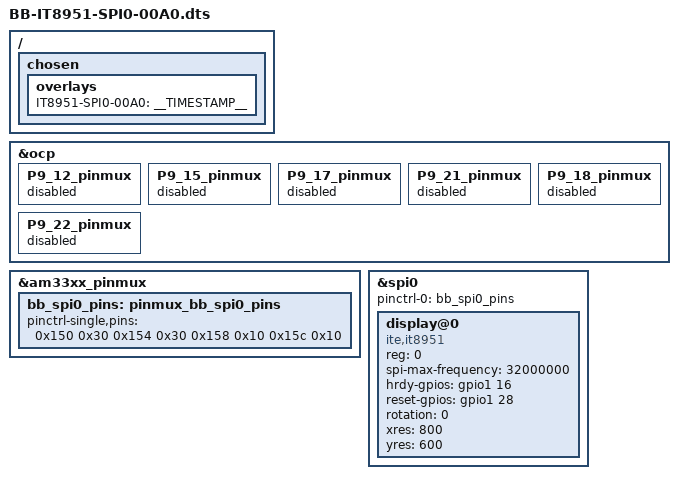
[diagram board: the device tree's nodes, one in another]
/*
 * Copyright (C) 2013 CircuitCo
 * Copyright (C) 2018 Drew Fustini <drew@beagleboard.org>
 * Copyright (C) 2019 Mark A. Yoder <mark.a.yoder@beagleboard.org>
 *
 * Waveshare Eink display on SPI0 bus using tinydrm it8951 driver
 *
 * LICENSE:
 * --------
 * This program is free software; you can redistribute it and/or modify
 * it under the terms of the GNU General Public License version 2 as
 * published by the Free Software Foundation.
 *
 * DOCUMENTATION:
 * --------------
 *
 *   P9.12 <--> reset
 *   P9.15 <--> hrdy
 *   P9.17 <--> cs
 *   P9.18 <--> mosi
 *   P9.21 <--> miso
 *   P9.22 <--> clk
 *
 */

#include <dt-bindings/gpio/gpio.h>
#include <dt-bindings/pinctrl/am33xx.h>
#include <dt-bindings/board/am335x-bbw-bbb-base.h>

/dts-v1/;
/plugin/;

/ {
	/*
	 * Helper to show loaded overlays under: /proc/device-tree/chosen/overlays/
	 */
	fragment@0 {
		target-path="/";
		__overlay__ {

			chosen {
				overlays {
					IT8951-SPI0-00A0 = __TIMESTAMP__;
				};
			};
		};
	};

	/*
	 * Free up the pins used by the cape from the pinmux helpers.
	 */

	fragment@1 {
		target = <&ocp>;
		__overlay__ {
			P9_12_pinmux { status = "disabled"; };	/* reset */
			P9_15_pinmux { status = "disabled"; };	/* hrdy */
			P9_17_pinmux { status = "disabled"; };	/* spi0_cs0 */
			P9_21_pinmux { status = "disabled"; };	/* spi0_d0 */
			P9_18_pinmux { status = "disabled"; };	/* spi0_d1 */
			P9_22_pinmux { status = "disabled"; };	/* spi0_sclk */
		};
	};

	fragment@2 {
		target = <&am33xx_pinmux>;
		__overlay__ {
			/* default state has all gpios released and mode set to uart1 */
			/* See page 1446 of am35xx TRM */
			bb_spi0_pins: pinmux_bb_spi0_pins {
				pinctrl-single,pins = <
					0x150 0x30	/* mcasp0_aclkx.spi0_sclk,  INPUT_PULLUP | MODE0 */
					0x154 0x30	/* mcasp0_fsx.spi0_d0,      INPUT_PULLUP | MODE0 */
					0x158 0x10	/* mcasp0_axr0.spi0_d1,    OUTPUT_PULLUP | MODE0 */
					0x15c 0x10	/* mcasp0_ahclkr.spi0_cs0, OUTPUT_PULLUP | MODE0 */
					// 0x164 0x12	/* eCAP0_in_PWM0_out.spi0_cs1 OUTPUT_PULLUP | MODE2 */
				>;
			};

		};
	};

	fragment@3 {
		target = <&spi0>;
		__overlay__ {
			#address-cells = <1>;
			#size-cells = <0>;

			status = "okay";
			pinctrl-names = "default";
			pinctrl-0 = <&bb_spi0_pins>;

			display@0{
				status = "okay";
				compatible = "ite,it8951";
				reg = <0>;
				spi-max-frequency = <32000000>;
				hrdy-gpios    = <&gpio1 16 0>;   // hrdy    P9.15 gpio1[16]
				reset-gpios = <&gpio1 28 0>;   // reset P9.12 gpio1[28]
				
				rotation = <0>;
				xres = <800>;
				yres = <600>;
			};
		};
	};
};
